# ZB204 register map
Vendor: GS; File version: 1.2
CPU: CM3 r2p0, little endian, MPU, no FPU, VTOR, 3 interrupt priority bits
Registers are 32-bit, read-write, reset 0x0 unless marked. A register's access mark holds for its fields unless they carry their own. Offsets are from the block's base; [hi:lo] are bit positions; {n}, {i} and the like mark numbered series.

## HRF
Base 0x40900000
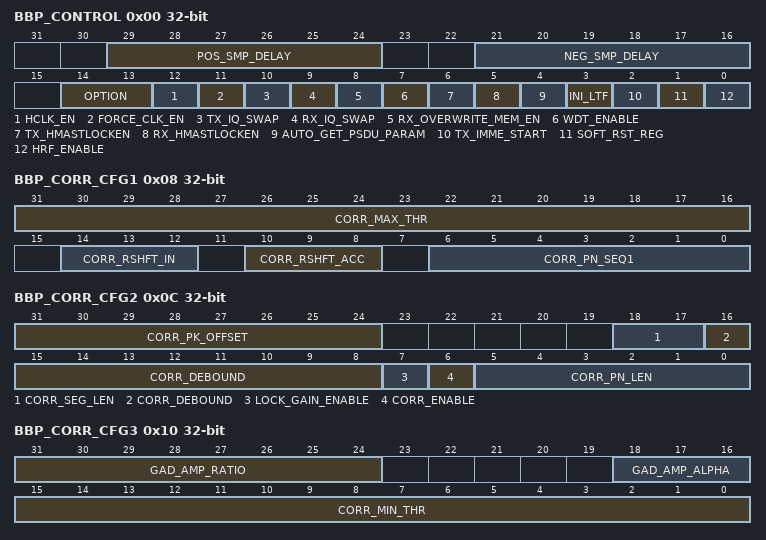
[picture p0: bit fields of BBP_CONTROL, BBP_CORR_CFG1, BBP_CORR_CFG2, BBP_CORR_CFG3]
0x00 BBP_CONTROL
  [29:24] POS_SMP_DELAY, [21:16] NEG_SMP_DELAY, [14:13] OPTION, [12] HCLK_EN, [11] FORCE_CLK_EN, [10] TX_IQ_SWAP, [9] RX_IQ_SWAP, [8] RX_OVERWRITE_MEM_EN, [7] WDT_ENABLE, [6] TX_HMASTLOCKEN, [5] RX_HMASTLOCKEN, [4] AUTO_GET_PSDU_PARAM, [3] INI_LTF, [2] TX_IMME_START, [1] SOFT_RST_REG, [0] HRF_ENABLE
0x04 BBP_CORR_CFG0
  [31:0] CORR_PN_SEQ0
0x08 BBP_CORR_CFG1
  [31:16] CORR_MAX_THR, [14:12] CORR_RSHFT_IN, [10:8] CORR_RSHFT_ACC, [6:0] CORR_PN_SEQ1
0x0C BBP_CORR_CFG2
  [31:24] CORR_PK_OFFSET, [18:17] CORR_SEG_LEN, [16:8] CORR_DEBOUND, [7] LOCK_GAIN_ENABLE, [6] CORR_ENABLE, [5:0] CORR_PN_LEN
0x10 BBP_CORR_CFG3
  [31:24] GAD_AMP_RATIO, [18:16] GAD_AMP_ALPHA, [15:0] CORR_MIN_THR
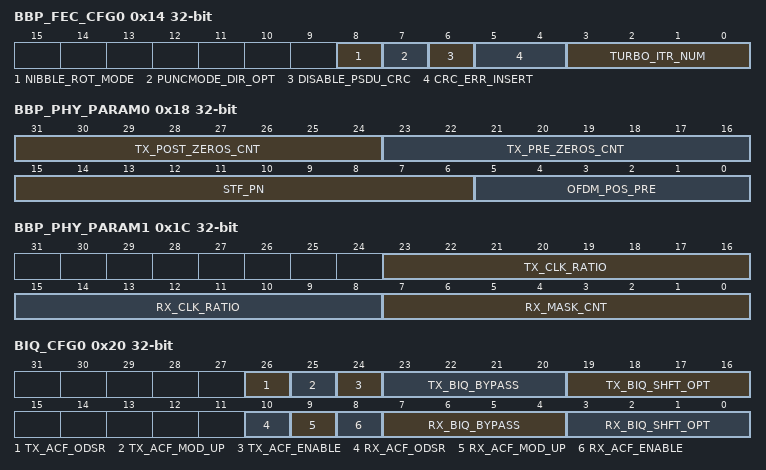
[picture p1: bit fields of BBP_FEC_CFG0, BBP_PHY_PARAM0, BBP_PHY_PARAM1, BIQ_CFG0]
0x14 BBP_FEC_CFG0
  [8] NIBBLE_ROT_MODE, [7] PUNCMODE_DIR_OPT, [6] DISABLE_PSDU_CRC, [5:4] CRC_ERR_INSERT, [3:0] TURBO_ITR_NUM
0x18 BBP_PHY_PARAM0
  [31:24] TX_POST_ZEROS_CNT, [23:16] TX_PRE_ZEROS_CNT, [15:6] STF_PN, [5:0] OFDM_POS_PRE
0x1C BBP_PHY_PARAM1
  [23:16] TX_CLK_RATIO, [15:8] RX_CLK_RATIO, [7:0] RX_MASK_CNT
0x20 BIQ_CFG0
  [26] TX_ACF_ODSR, [25] TX_ACF_MOD_UP, [24] TX_ACF_ENABLE, [23:20] TX_BIQ_BYPASS, [19:16] TX_BIQ_SHFT_OPT, [10] RX_ACF_ODSR, [9] RX_ACF_MOD_UP, [8] RX_ACF_ENABLE, [7:4] RX_BIQ_BYPASS, [3:0] RX_BIQ_SHFT_OPT
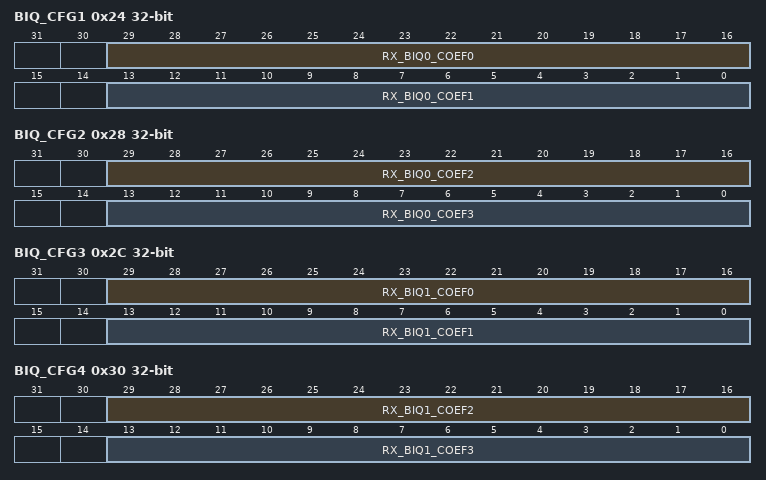
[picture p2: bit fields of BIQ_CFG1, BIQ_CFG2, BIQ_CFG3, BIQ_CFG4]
0x24 BIQ_CFG1
  [29:16] RX_BIQ0_COEF0, [13:0] RX_BIQ0_COEF1
0x28 BIQ_CFG2
  [29:16] RX_BIQ0_COEF2, [13:0] RX_BIQ0_COEF3
0x2C BIQ_CFG3
  [29:16] RX_BIQ1_COEF0, [13:0] RX_BIQ1_COEF1
0x30 BIQ_CFG4
  [29:16] RX_BIQ1_COEF2, [13:0] RX_BIQ1_COEF3
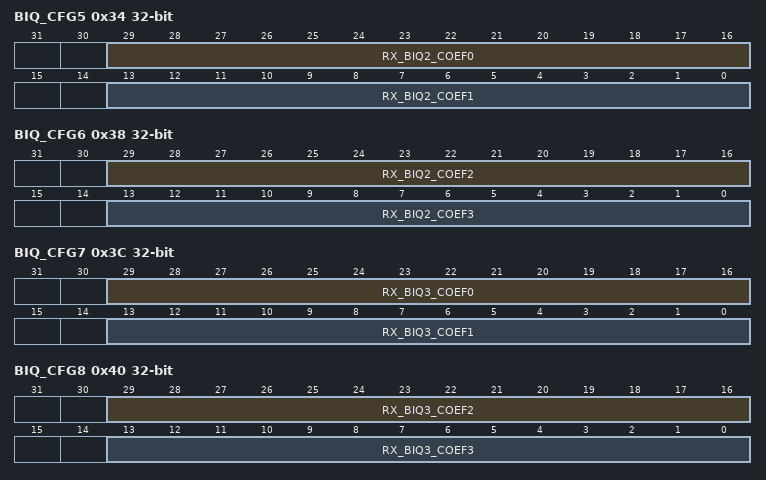
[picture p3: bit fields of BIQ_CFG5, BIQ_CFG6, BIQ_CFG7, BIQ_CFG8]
0x34 BIQ_CFG5
  [29:16] RX_BIQ2_COEF0, [13:0] RX_BIQ2_COEF1
0x38 BIQ_CFG6
  [29:16] RX_BIQ2_COEF2, [13:0] RX_BIQ2_COEF3
0x3C BIQ_CFG7
  [29:16] RX_BIQ3_COEF0, [13:0] RX_BIQ3_COEF1
0x40 BIQ_CFG8
  [29:16] RX_BIQ3_COEF2, [13:0] RX_BIQ3_COEF3
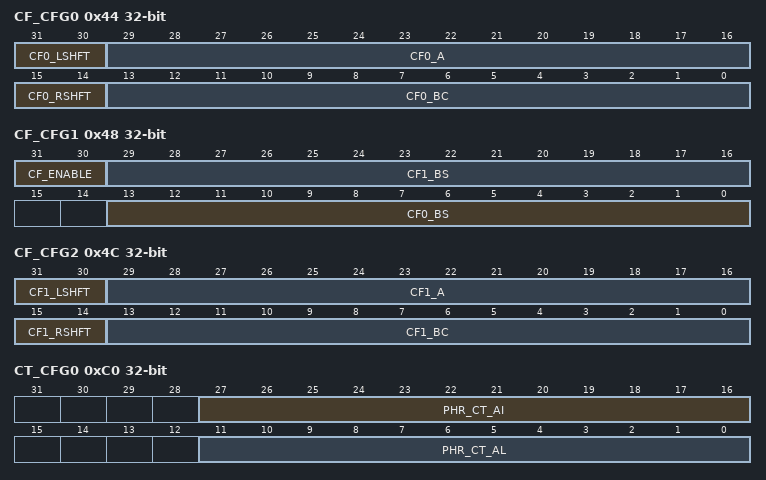
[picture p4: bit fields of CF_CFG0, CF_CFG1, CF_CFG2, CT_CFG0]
0x44 CF_CFG0
  [31:30] CF0_LSHFT, [29:16] CF0_A, [15:14] CF0_RSHFT, [13:0] CF0_BC
0x48 CF_CFG1
  [31:30] CF_ENABLE, [29:16] CF1_BS, [13:0] CF0_BS
0x4C CF_CFG2
  [31:30] CF1_LSHFT, [29:16] CF1_A, [15:14] CF1_RSHFT, [13:0] CF1_BC
{0x50+4i} BBP_TONEMASK[{i}] (i=0..3) — BBP_TONEMASK0
  [31:0] TONE_MASK0
{0x60+4i} BBP_LTF_FREQ[{i}] (i=0..3) — BBP_LTF_FREQ1
  [31:0] LTF_FREQ1
{0x70+4i} BBP_STF_DATA[{i}] (i=0..15) — BBP_STF_DATA0
  [23:0] STF_DATA0
{0xB0+4i} BBP_PILOT_TONE[{i}] (i=0..3) — BBP_PILOT_TONE0
  [31:0] PILOT_TONE0
0xC0 CT_CFG0
  [27:16] PHR_CT_AI, [11:0] PHR_CT_AL
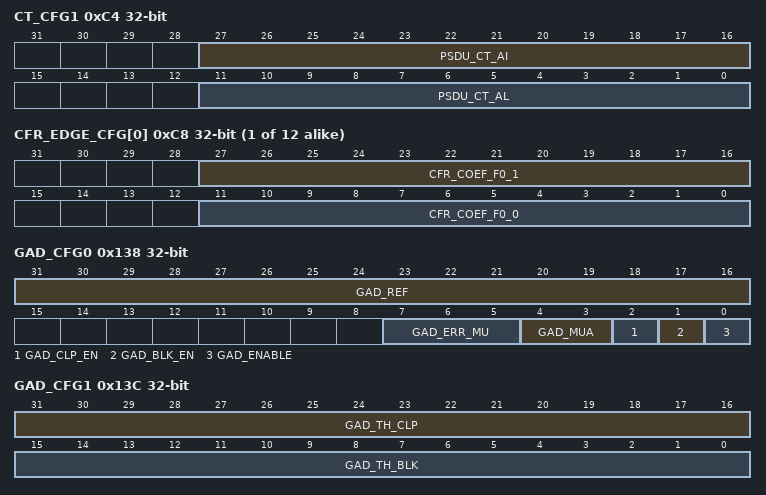
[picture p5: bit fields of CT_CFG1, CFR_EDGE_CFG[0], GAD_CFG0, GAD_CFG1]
0xC4 CT_CFG1
  [27:16] PSDU_CT_AI, [11:0] PSDU_CT_AL
{0xC8+4i} CFR_EDGE_CFG[{i}] (i=0..11) — CFR_EDGE0_CFG0
  [27:16] CFR_COEF_F0_1, [11:0] CFR_COEF_F0_0
{0xF8+4i} BBP_SIG_MAP[{i}] (i=0..15) — BBP_SIG_MAP0_0
  [31:0] SIG_MAP0_0
0x138 GAD_CFG0
  [31:16] GAD_REF, [7:5] GAD_ERR_MU, [4:3] GAD_MUA, [2] GAD_CLP_EN, [1] GAD_BLK_EN, [0] GAD_ENABLE
0x13C GAD_CFG1
  [31:16] GAD_TH_CLP, [15:0] GAD_TH_BLK
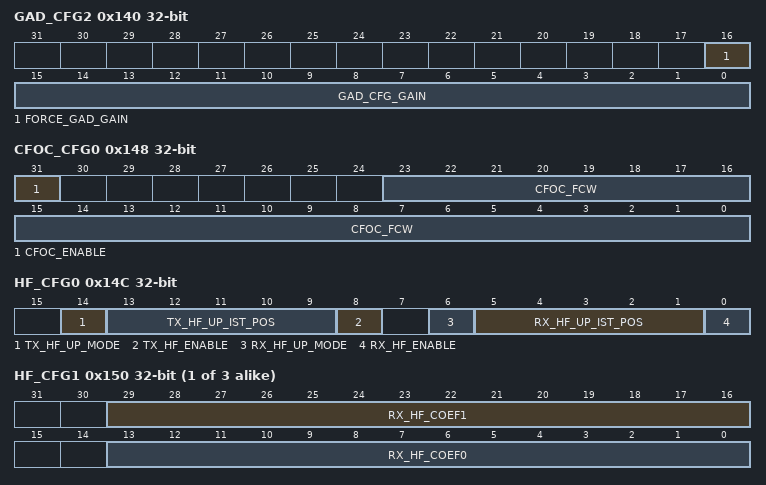
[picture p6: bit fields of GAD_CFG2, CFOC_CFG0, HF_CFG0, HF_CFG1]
0x140 GAD_CFG2
  [16] FORCE_GAD_GAIN, [15:0] GAD_CFG_GAIN
0x144 GAD_GAIN
  [23:0] GAD_GAIN
0x148 CFOC_CFG0
  [31] CFOC_ENABLE, [23:0] CFOC_FCW
0x14C HF_CFG0
  [14] TX_HF_UP_MODE, [13:9] TX_HF_UP_IST_POS, [8] TX_HF_ENABLE, [6] RX_HF_UP_MODE, [5:1] RX_HF_UP_IST_POS, [0] RX_HF_ENABLE
{0x14C+4i} HF_CFG{i} (i=1..3)
  [29:16] RX_HF_COEF{2i-1}, [13:0] RX_HF_COEF{2i-2}
0x15C HF_CFG4
  [13:0] RX_HF_COEF6
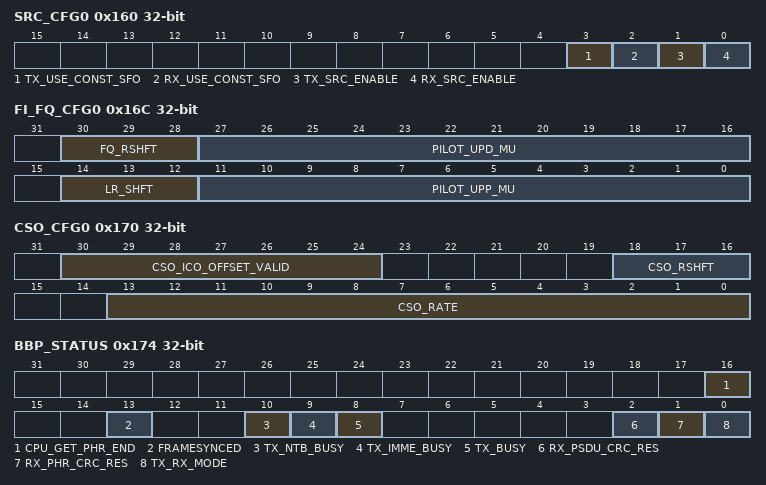
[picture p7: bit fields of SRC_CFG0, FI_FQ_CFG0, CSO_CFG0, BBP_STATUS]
0x160 SRC_CFG0
  [3] TX_USE_CONST_SFO, [2] RX_USE_CONST_SFO, [1] TX_SRC_ENABLE, [0] RX_SRC_ENABLE
0x164 SRC_CFG1
  [23:0] TX_CONST_SFO
0x168 SRC_CFG2
  [23:0] RX_CONST_SFO
0x16C FI_FQ_CFG0
  [30:28] FQ_RSHFT, [27:16] PILOT_UPD_MU, [14:12] LR_SHFT, [11:0] PILOT_UPP_MU
0x170 CSO_CFG0
  [30:24] CSO_ICO_OFFSET_VALID, [18:16] CSO_RSHFT, [13:0] CSO_RATE
0x174 BBP_STATUS
  [16] CPU_GET_PHR_END, [13] FRAMESYNCED, [10] TX_NTB_BUSY, [9] TX_IMME_BUSY, [8] TX_BUSY, [2] RX_PSDU_CRC_RES, [1] RX_PHR_CRC_RES, [0] TX_RX_MODE
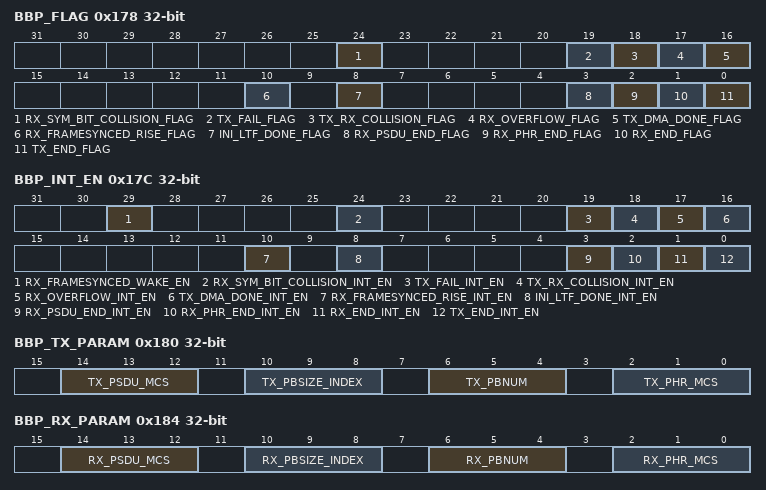
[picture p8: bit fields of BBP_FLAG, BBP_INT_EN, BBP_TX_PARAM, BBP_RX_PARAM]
0x178 BBP_FLAG
  [24] RX_SYM_BIT_COLLISION_FLAG, [19] TX_FAIL_FLAG, [18] TX_RX_COLLISION_FLAG, [17] RX_OVERFLOW_FLAG, [16] TX_DMA_DONE_FLAG, [10] RX_FRAMESYNCED_RISE_FLAG, [8] INI_LTF_DONE_FLAG, [3] RX_PSDU_END_FLAG, [2] RX_PHR_END_FLAG, [1] RX_END_FLAG, [0] TX_END_FLAG
0x17C BBP_INT_EN
  [29] RX_FRAMESYNCED_WAKE_EN, [24] RX_SYM_BIT_COLLISION_INT_EN, [19] TX_FAIL_INT_EN, [18] TX_RX_COLLISION_INT_EN, [17] RX_OVERFLOW_INT_EN, [16] TX_DMA_DONE_INT_EN, [10] RX_FRAMESYNCED_RISE_INT_EN, [8] INI_LTF_DONE_INT_EN, [3] RX_PSDU_END_INT_EN, [2] RX_PHR_END_INT_EN, [1] RX_END_INT_EN, [0] TX_END_INT_EN
0x180 BBP_TX_PARAM
  [14:12] TX_PSDU_MCS, [10:8] TX_PBSIZE_INDEX, [6:4] TX_PBNUM, [2:0] TX_PHR_MCS
0x184 BBP_RX_PARAM
  [14:12] RX_PSDU_MCS, [10:8] RX_PBSIZE_INDEX, [6:4] RX_PBNUM, [2:0] RX_PHR_MCS
0x188 BBP_RX_BASE_ADDR
  [31:0] RX_BASE_ADDR
0x18C BBP_TX_BASE_ADDR
  [31:0] TX_BASE_ADDR
0x190 ENCRYPT0
  [31:0] ENCRYPT_CODE0
0x194 ENCRYPT1
  [31:0] ENCRYPT_CODE1
0x198 RXWDTCFG
  [31:0] WDT_TIMEOUT_THR
0x19C SIG_PWR
  [31:0] SIG_POW
0x1A0 NOISE_PWR
  [31:0] NOS_POW
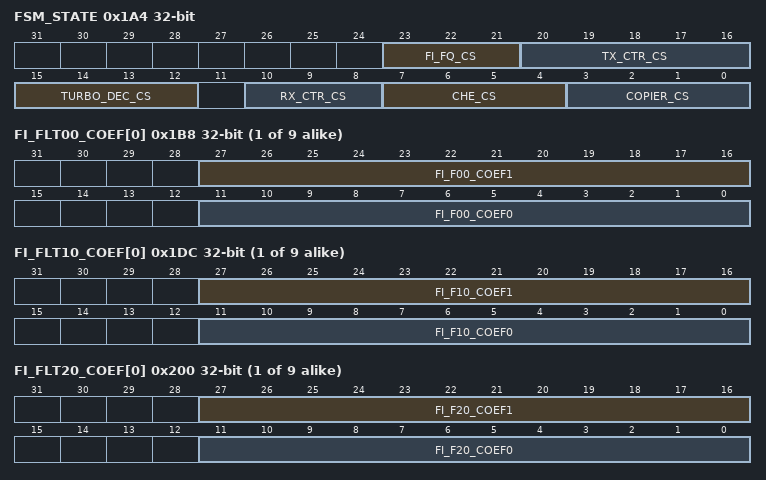
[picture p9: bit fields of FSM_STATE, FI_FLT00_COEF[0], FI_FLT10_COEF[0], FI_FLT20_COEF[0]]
0x1A4 FSM_STATE
  [23:21] FI_FQ_CS, [20:16] TX_CTR_CS, [15:12] TURBO_DEC_CS, [10:8] RX_CTR_CS, [7:4] CHE_CS, [3:0] COPIER_CS
0x1A8 LTF_FFT_COEFF
  [13:0] LTF_FFT_COEFF
0x1AC LTF_IFFT_COEFF
  [13:0] LTF_IFFT_COEFF
0x1B0 RX_FFT_COEFF
  [13:0] RX_FFT_COEFF
0x1B4 TX_IFFT_COEFF
  [13:0] TX_IFFT_COEFF
{0x1B8+4i} FI_FLT00_COEF[{i}] (i=0..8)
  [27:16] FI_F00_COEF1, [11:0] FI_F00_COEF0
{0x1DC+4i} FI_FLT10_COEF[{i}] (i=0..8) — FI_FLT10_COEF0
  [27:16] FI_F10_COEF1, [11:0] FI_F10_COEF0
{0x200+4i} FI_FLT20_COEF[{i}] (i=0..8) — FI_FLT20_COEF[{i}]
  [27:16] FI_F20_COEF1, [11:0] FI_F20_COEF0
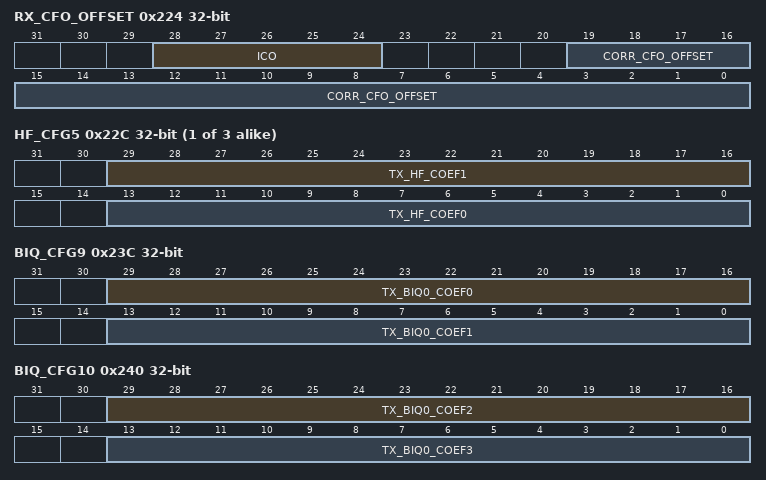
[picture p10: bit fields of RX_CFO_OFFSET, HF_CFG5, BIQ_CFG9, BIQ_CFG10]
0x224 RX_CFO_OFFSET
  [28:24] ICO, [19:0] CORR_CFO_OFFSET
0x228 CO_TOT
  [23:0] CO_TOT
{0x218+4i} HF_CFG{i} (i=5..7)
  [29:16] TX_HF_COEF{2i-9}, [13:0] TX_HF_COEF{2i-10}
0x238 HF_CFG8
  [13:0] TX_HF_COEF6
0x23C BIQ_CFG9
  [29:16] TX_BIQ0_COEF0, [13:0] TX_BIQ0_COEF1
0x240 BIQ_CFG10
  [29:16] TX_BIQ0_COEF2, [13:0] TX_BIQ0_COEF3
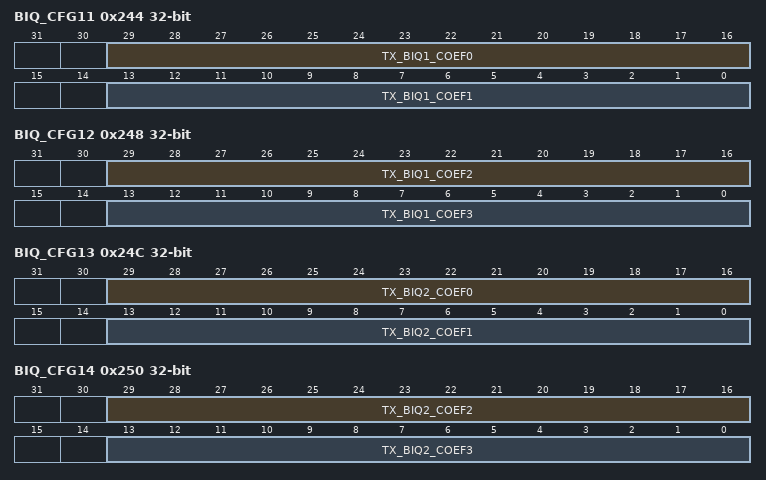
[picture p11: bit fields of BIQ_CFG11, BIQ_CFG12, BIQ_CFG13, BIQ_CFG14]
0x244 BIQ_CFG11
  [29:16] TX_BIQ1_COEF0, [13:0] TX_BIQ1_COEF1
0x248 BIQ_CFG12
  [29:16] TX_BIQ1_COEF2, [13:0] TX_BIQ1_COEF3
0x24C BIQ_CFG13
  [29:16] TX_BIQ2_COEF0, [13:0] TX_BIQ2_COEF1
0x250 BIQ_CFG14
  [29:16] TX_BIQ2_COEF2, [13:0] TX_BIQ2_COEF3
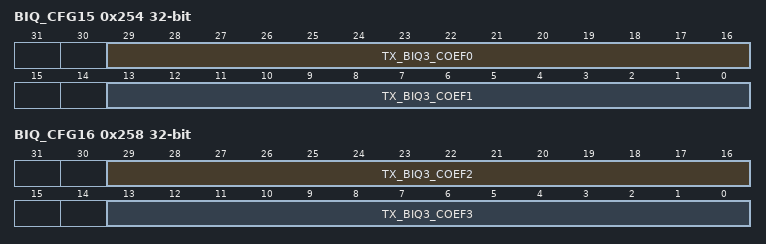
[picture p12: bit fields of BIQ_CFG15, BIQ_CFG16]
0x254 BIQ_CFG15
  [29:16] TX_BIQ3_COEF0, [13:0] TX_BIQ3_COEF1
0x258 BIQ_CFG16
  [29:16] TX_BIQ3_COEF2, [13:0] TX_BIQ3_COEF3
